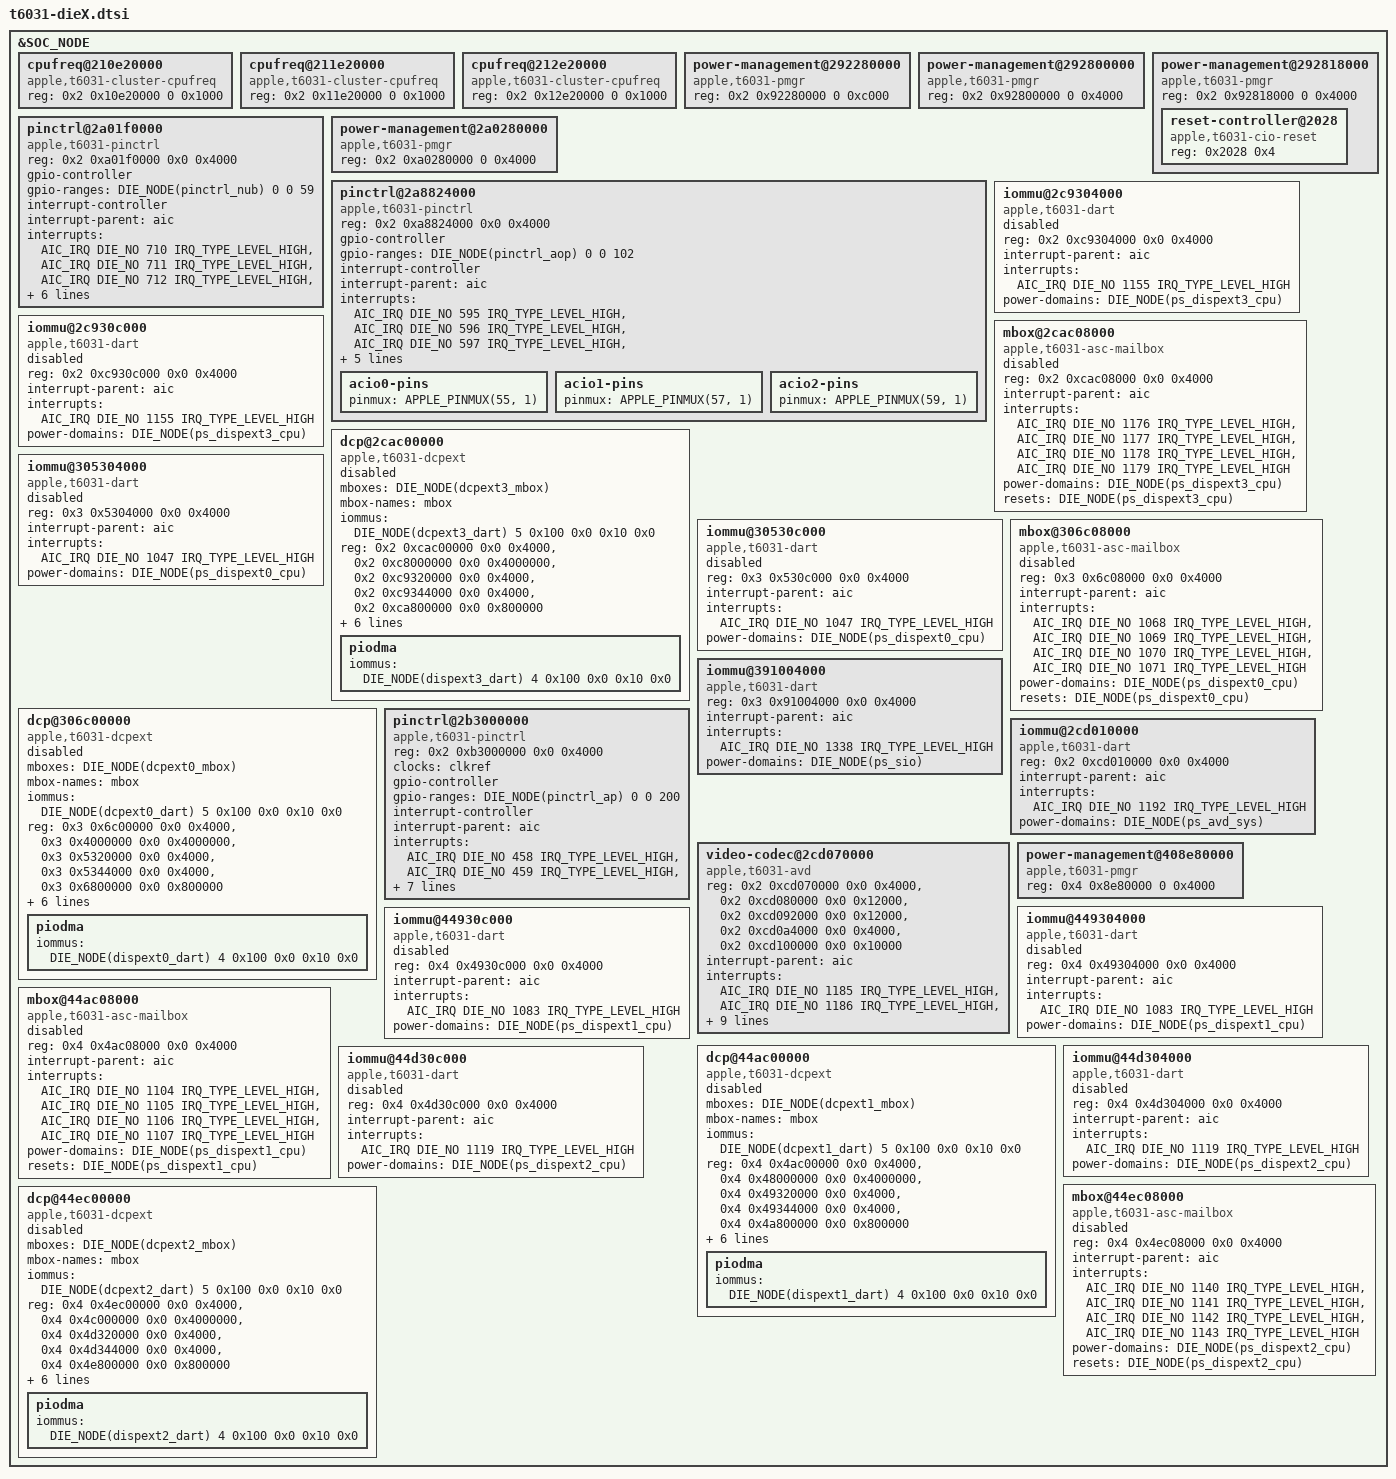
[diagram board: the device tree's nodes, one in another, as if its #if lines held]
// SPDX-License-Identifier: GPL-2.0+ OR MIT
/*
 * Nodes present on both dies of T6032 (M3 Ultra) and present on T6031 / T6034
 * (M3 Max).
 *
 * Copyright The Asahi Linux Contributors
 */

&SOC_NODE {
	DIE_NODE(cpufreq_e): cpufreq@210e20000 {
		compatible = "apple,t6031-cluster-cpufreq", "apple,t8112-cluster-cpufreq";
		reg = <0x2 0x10e20000 0 0x1000>;
		#performance-domain-cells = <0>;
	};

	DIE_NODE(cpufreq_p0): cpufreq@211e20000 {
		compatible = "apple,t6031-cluster-cpufreq", "apple,t8112-cluster-cpufreq";
		reg = <0x2 0x11e20000 0 0x1000>;
		#performance-domain-cells = <0>;
	};

	DIE_NODE(cpufreq_p1): cpufreq@212e20000 {
		compatible = "apple,t6031-cluster-cpufreq", "apple,t8112-cluster-cpufreq";
		reg = <0x2 0x12e20000 0 0x1000>;
		#performance-domain-cells = <0>;
	};

	DIE_NODE(pmgr): power-management@292280000 {
		compatible = "apple,t6031-pmgr", "apple,t8103-pmgr",
			     "syscon", "simple-mfd";
		reg = <0x2 0x92280000 0 0xc000>;
		#address-cells = <1>;
		#size-cells = <1>;
	};

	DIE_NODE(pmgr1): power-management@292800000 {
		compatible = "apple,t6031-pmgr", "apple,t8103-pmgr",
			     "syscon", "simple-mfd";
		reg = <0x2 0x92800000 0 0x4000>;
		#address-cells = <1>;
		#size-cells = <1>;
	};

	DIE_NODE(pmgr_cio): power-management@292818000 {
		compatible = "apple,t6031-pmgr", "apple,t8103-pmgr", "syscon", "simple-mfd";
		#address-cells = <1>;
		#size-cells = <1>;

		reg = <0x2 0x92818000 0 0x4000>;

		DIE_NODE(cio_reset): reset-controller@2028 {
			compatible = "apple,t6031-cio-reset", "apple,t6000-cio-reset";
			reg = <0x2028 0x4>;
			#reset-cells = <1>;
		};
	};

	DIE_NODE(pinctrl_nub): pinctrl@2a01f0000 {
		compatible = "apple,t6031-pinctrl", "apple,t8103-pinctrl";
		reg = <0x2 0xa01f0000 0x0 0x4000>;

		#gpio-cells = <2>;
		gpio-controller;
		gpio-ranges = <&DIE_NODE(pinctrl_nub) 0 0 59>;

		#interrupt-cells = <2>;
		interrupt-controller;
		interrupt-parent = <&aic>;
		interrupts = <AIC_IRQ DIE_NO 710 IRQ_TYPE_LEVEL_HIGH>,
			     <AIC_IRQ DIE_NO 711 IRQ_TYPE_LEVEL_HIGH>,
			     <AIC_IRQ DIE_NO 712 IRQ_TYPE_LEVEL_HIGH>,
			     <AIC_IRQ DIE_NO 713 IRQ_TYPE_LEVEL_HIGH>,
			     <AIC_IRQ DIE_NO 714 IRQ_TYPE_LEVEL_HIGH>,
			     <AIC_IRQ DIE_NO 715 IRQ_TYPE_LEVEL_HIGH>,
			     <AIC_IRQ DIE_NO 716 IRQ_TYPE_LEVEL_HIGH>;

		power-domains = <&DIE_NODE(ps_nub_gpio)>;
		apple,npins = <59>;
	};

	DIE_NODE(pmgr_mini): power-management@2a0280000 {
		compatible = "apple,t6031-pmgr", "apple,t8103-pmgr",
			     "syscon", "simple-mfd";
		reg = <0x2 0xa0280000 0 0x4000>;
		#address-cells = <1>;
		#size-cells = <1>;
	};

	DIE_NODE(pinctrl_aop): pinctrl@2a8824000 {
		compatible = "apple,t6031-pinctrl", "apple,t8103-pinctrl";
		reg = <0x2 0xa8824000 0x0 0x4000>;

		#gpio-cells = <2>;
		gpio-controller;
		gpio-ranges = <&DIE_NODE(pinctrl_aop) 0 0 102>;

		#interrupt-cells = <2>;
		interrupt-controller;
		interrupt-parent = <&aic>;
		interrupts = <AIC_IRQ DIE_NO 595 IRQ_TYPE_LEVEL_HIGH>,
			     <AIC_IRQ DIE_NO 596 IRQ_TYPE_LEVEL_HIGH>,
			     <AIC_IRQ DIE_NO 597 IRQ_TYPE_LEVEL_HIGH>,
			     <AIC_IRQ DIE_NO 598 IRQ_TYPE_LEVEL_HIGH>,
			     <AIC_IRQ DIE_NO 599 IRQ_TYPE_LEVEL_HIGH>,
			     <AIC_IRQ DIE_NO 600 IRQ_TYPE_LEVEL_HIGH>,
			     <AIC_IRQ DIE_NO 601 IRQ_TYPE_LEVEL_HIGH>;

		apple,npins = <102>;

		DIE_NODE(acio0_pins): acio0-pins {
			pinmux = <APPLE_PINMUX(55, 1)>;
		};

		DIE_NODE(acio1_pins): acio1-pins {
			pinmux = <APPLE_PINMUX(57, 1)>;
		};

		DIE_NODE(acio2_pins): acio2-pins {
			pinmux = <APPLE_PINMUX(59, 1)>;
		};
	};

	DIE_NODE(dispext3_dart): iommu@2c9304000 {
		compatible = "apple,t6031-dart", "apple,t8110-dart";
		reg = <0x2 0xc9304000 0x0 0x4000>;
		#iommu-cells = <5>;
		interrupt-parent = <&aic>;
		interrupts = <AIC_IRQ DIE_NO 1155 IRQ_TYPE_LEVEL_HIGH>;
		power-domains = <&DIE_NODE(ps_dispext3_cpu)>;
		status = "disabled";
	};

	DIE_NODE(dcpext3_dart): iommu@2c930c000 {
		compatible = "apple,t6031-dart", "apple,t8110-dart";
		reg = <0x2 0xc930c000 0x0 0x4000>;
		#iommu-cells = <5>;
		interrupt-parent = <&aic>;
		interrupts = <AIC_IRQ DIE_NO 1155 IRQ_TYPE_LEVEL_HIGH>;
		power-domains = <&DIE_NODE(ps_dispext3_cpu)>;
		status = "disabled";
	};

	DIE_NODE(dcpext3_mbox): mbox@2cac08000 {
		compatible = "apple,t6031-asc-mailbox", "apple,asc-mailbox-v4";
		reg = <0x2 0xcac08000 0x0 0x4000>;
		interrupt-parent = <&aic>;
		interrupts = <AIC_IRQ DIE_NO 1176 IRQ_TYPE_LEVEL_HIGH>,
			     <AIC_IRQ DIE_NO 1177 IRQ_TYPE_LEVEL_HIGH>,
			     <AIC_IRQ DIE_NO 1178 IRQ_TYPE_LEVEL_HIGH>,
			     <AIC_IRQ DIE_NO 1179 IRQ_TYPE_LEVEL_HIGH>;
		interrupt-names = "send-empty", "send-not-empty",
				  "recv-empty", "recv-not-empty";
		#mbox-cells = <0>;
		power-domains = <&DIE_NODE(ps_dispext3_cpu)>;
		resets = <&DIE_NODE(ps_dispext3_cpu)>;
		status = "disabled";
	};

	DIE_NODE(dcpext3):  dcp@2cac00000 {
		compatible = "apple,t6031-dcpext", "apple,dcpext";
		mboxes = <&DIE_NODE(dcpext3_mbox)>;
		mbox-names = "mbox";
		iommus = <&DIE_NODE(dcpext3_dart) 5 0x100 0x0 0x10 0x0>;

		reg-names = "coproc", "disp-0", "disp-1", "disp-2", "disp-3";
		reg = <0x2 0xcac00000 0x0 0x4000>,
		      <0x2 0xc8000000 0x0 0x4000000>,
		      <0x2 0xc9320000 0x0 0x4000>,
		      <0x2 0xc9344000 0x0 0x4000>,
		      <0x2 0xca800000 0x0 0x800000>;
		power-domains = <&DIE_NODE(ps_dispext3_cpu)>;
		resets = <&DIE_NODE(ps_dispext3_cpu)>;
		clocks = <&DIE_NODE(clk_dispext3)>;
		phandle = <&DIE_NODE(dcpext3)>;
		// required bus properties for 'piodma' subdevice
		#address-cells = <2>;
		#size-cells = <2>;
		apple,bw-scratch = <&pmgr_dcp 0 4 0x1228>;
		apple,dcp-index = <3>;
		apple,iomfb-surfaces = <1 1 0 1>;
		status = "disabled";

		piodma {
			iommus = <&DIE_NODE(dispext3_dart) 4 0x100 0x0 0x10 0x0>;
		};
	};

	DIE_NODE(dispext0_dart): iommu@305304000 {
		compatible = "apple,t6031-dart", "apple,t8110-dart";
		reg = <0x3 0x5304000 0x0 0x4000>;
		#iommu-cells = <5>;
		interrupt-parent = <&aic>;
		interrupts = <AIC_IRQ DIE_NO 1047 IRQ_TYPE_LEVEL_HIGH>;
		power-domains = <&DIE_NODE(ps_dispext0_cpu)>;
		status = "disabled";
	};

	DIE_NODE(dcpext0_dart): iommu@30530c000 {
		compatible = "apple,t6031-dart", "apple,t8110-dart";
		reg = <0x3 0x530c000 0x0 0x4000>;
		#iommu-cells = <5>;
		interrupt-parent = <&aic>;
		interrupts = <AIC_IRQ DIE_NO 1047 IRQ_TYPE_LEVEL_HIGH>;
		power-domains = <&DIE_NODE(ps_dispext0_cpu)>;
		status = "disabled";
	};

	DIE_NODE(dcpext0_mbox): mbox@306c08000 {
		compatible = "apple,t6031-asc-mailbox", "apple,asc-mailbox-v4";
		reg = <0x3 0x6c08000 0x0 0x4000>;
		interrupt-parent = <&aic>;
		interrupts = <AIC_IRQ DIE_NO 1068 IRQ_TYPE_LEVEL_HIGH>,
			     <AIC_IRQ DIE_NO 1069 IRQ_TYPE_LEVEL_HIGH>,
			     <AIC_IRQ DIE_NO 1070 IRQ_TYPE_LEVEL_HIGH>,
			     <AIC_IRQ DIE_NO 1071 IRQ_TYPE_LEVEL_HIGH>;
		interrupt-names = "send-empty", "send-not-empty",
				  "recv-empty", "recv-not-empty";
		#mbox-cells = <0>;
		power-domains = <&DIE_NODE(ps_dispext0_cpu)>;
		resets = <&DIE_NODE(ps_dispext0_cpu)>;
		status = "disabled";
	};

	DIE_NODE(dcpext0):  dcp@306c00000 {
		compatible = "apple,t6031-dcpext", "apple,dcpext";
		mboxes = <&DIE_NODE(dcpext0_mbox)>;
		mbox-names = "mbox";
		iommus = <&DIE_NODE(dcpext0_dart) 5 0x100 0x0 0x10 0x0>;

		reg-names = "coproc", "disp-0", "disp-1", "disp-2", "disp-3";
		reg = <0x3 0x6c00000 0x0 0x4000>,
		      <0x3 0x4000000 0x0 0x4000000>,
		      <0x3 0x5320000 0x0 0x4000>,
		      <0x3 0x5344000 0x0 0x4000>,
		      <0x3 0x6800000 0x0 0x800000>;
		power-domains = <&DIE_NODE(ps_dispext0_cpu)>;
		resets = <&DIE_NODE(ps_dispext0_cpu)>;
		clocks = <&DIE_NODE(clk_dispext0)>;
		phandle = <&DIE_NODE(dcpext0)>;
		// required bus properties for 'piodma' subdevice
		#address-cells = <2>;
		#size-cells = <2>;
		apple,bw-scratch = <&pmgr_dcp 0 4 0x1210>;
		apple,dcp-index = <0>;
		apple,iomfb-surfaces = <1 1 0 1>;
		status = "disabled";

		piodma {
			iommus = <&DIE_NODE(dispext0_dart) 4 0x100 0x0 0x10 0x0>;
		};
	};

	DIE_NODE(sio_dart): iommu@391004000 {
		compatible = "apple,t6031-dart", "apple,t8110-dart";
		reg = <0x3 0x91004000 0x0 0x4000>;
		interrupt-parent = <&aic>;
		interrupts = <AIC_IRQ DIE_NO 1338 IRQ_TYPE_LEVEL_HIGH>;
		#iommu-cells = <1>;
		power-domains = <&DIE_NODE(ps_sio)>;
	};

	DIE_NODE(pinctrl_ap): pinctrl@2b3000000 {
		compatible = "apple,t6031-pinctrl", "apple,t8103-pinctrl";
		reg = <0x2 0xb3000000 0x0 0x4000>;

		clocks = <&clkref>;

		#gpio-cells = <2>;
		gpio-controller;
		gpio-ranges = <&DIE_NODE(pinctrl_ap) 0 0 200>;

		#interrupt-cells = <2>;
		interrupt-controller;
		interrupt-parent = <&aic>;
		interrupts = <AIC_IRQ DIE_NO 458 IRQ_TYPE_LEVEL_HIGH>,
			     <AIC_IRQ DIE_NO 459 IRQ_TYPE_LEVEL_HIGH>,
			     <AIC_IRQ DIE_NO 460 IRQ_TYPE_LEVEL_HIGH>,
			     <AIC_IRQ DIE_NO 461 IRQ_TYPE_LEVEL_HIGH>,
			     <AIC_IRQ DIE_NO 462 IRQ_TYPE_LEVEL_HIGH>,
			     <AIC_IRQ DIE_NO 463 IRQ_TYPE_LEVEL_HIGH>,
			     <AIC_IRQ DIE_NO 464 IRQ_TYPE_LEVEL_HIGH>;

		power-domains = <&DIE_NODE(ps_gpio)>;
		apple,npins = <200>;
	};

	DIE_NODE(avd_dart): iommu@2cd010000 {
		compatible = "apple,t6031-dart", "apple,t8110-dart";
		reg = <0x2 0xcd010000 0x0 0x4000>;
		interrupt-parent = <&aic>;
		interrupts = <AIC_IRQ DIE_NO 1192 IRQ_TYPE_LEVEL_HIGH>;
		#iommu-cells = <1>;
		power-domains = <&DIE_NODE(ps_avd_sys)>;
	};

	video-codec@2cd070000 {
		compatible = "apple,t6031-avd", "apple,t8122-avd";
		reg = <0x2 0xcd070000 0x0 0x4000>,
		      <0x2 0xcd080000 0x0 0x12000>,
		      <0x2 0xcd092000 0x0 0x12000>,
		      <0x2 0xcd0a4000 0x0 0x4000>,
		      <0x2 0xcd100000 0x0 0x10000>;
		reg-names = "piodma", "code", "sram", "mbox", "ctrl";
		interrupt-parent = <&aic>;
		interrupts = <AIC_IRQ DIE_NO 1185 IRQ_TYPE_LEVEL_HIGH>,
			     <AIC_IRQ DIE_NO 1186 IRQ_TYPE_LEVEL_HIGH>,
			     <AIC_IRQ DIE_NO 1187 IRQ_TYPE_LEVEL_HIGH>,
			     <AIC_IRQ DIE_NO 1188 IRQ_TYPE_LEVEL_HIGH>,
			     <AIC_IRQ DIE_NO 1189 IRQ_TYPE_LEVEL_HIGH>,
			     <AIC_IRQ DIE_NO 1190 IRQ_TYPE_LEVEL_HIGH>,
			     <AIC_IRQ DIE_NO 1191 IRQ_TYPE_LEVEL_HIGH>;
		interrupt-names = "mbox0", "mbox1", "mbox2", "mbox3",
				  "flag0", "flag1", "piodma";
		iommus = <&DIE_NODE(avd_dart) 0>, <&DIE_NODE(avd_dart) 1>;
		#if defined(APPLE_USE_PMP)
		power-domains = <&DIE_NODE(pmp_report_avd_sys)>;
		#else
		power-domains = <&DIE_NODE(ps_avd_sys)>;
		#endif
		resets = <&DIE_NODE(ps_avd_sys)>;
	};

	DIE_NODE(pmgr_gfx): power-management@408e80000 {
		compatible = "apple,t6031-pmgr", "apple,t8103-pmgr",
			     "syscon", "simple-mfd";
		reg = <0x4 0x8e80000 0 0x4000>;
		#address-cells = <1>;
		#size-cells = <1>;
	};

	DIE_NODE(dispext1_dart): iommu@449304000 {
		compatible = "apple,t6031-dart", "apple,t8110-dart";
		reg = <0x4 0x49304000 0x0 0x4000>;
		#iommu-cells = <5>;
		interrupt-parent = <&aic>;
		interrupts = <AIC_IRQ DIE_NO 1083 IRQ_TYPE_LEVEL_HIGH>;
		power-domains = <&DIE_NODE(ps_dispext1_cpu)>;
		status = "disabled";
	};

	DIE_NODE(dcpext1_dart): iommu@44930c000 {
		compatible = "apple,t6031-dart", "apple,t8110-dart";
		reg = <0x4 0x4930c000 0x0 0x4000>;
		#iommu-cells = <5>;
		interrupt-parent = <&aic>;
		interrupts = <AIC_IRQ DIE_NO 1083 IRQ_TYPE_LEVEL_HIGH>;
		power-domains = <&DIE_NODE(ps_dispext1_cpu)>;
		status = "disabled";
	};

	DIE_NODE(dcpext1_mbox): mbox@44ac08000 {
		compatible = "apple,t6031-asc-mailbox", "apple,asc-mailbox-v4";
		reg = <0x4 0x4ac08000 0x0 0x4000>;
		interrupt-parent = <&aic>;
		interrupts = <AIC_IRQ DIE_NO 1104 IRQ_TYPE_LEVEL_HIGH>,
			     <AIC_IRQ DIE_NO 1105 IRQ_TYPE_LEVEL_HIGH>,
			     <AIC_IRQ DIE_NO 1106 IRQ_TYPE_LEVEL_HIGH>,
			     <AIC_IRQ DIE_NO 1107 IRQ_TYPE_LEVEL_HIGH>;
		interrupt-names = "send-empty", "send-not-empty",
				  "recv-empty", "recv-not-empty";
		#mbox-cells = <0>;
		power-domains = <&DIE_NODE(ps_dispext1_cpu)>;
		resets = <&DIE_NODE(ps_dispext1_cpu)>;
		status = "disabled";
	};

	DIE_NODE(dcpext1):  dcp@44ac00000 {
		compatible = "apple,t6031-dcpext", "apple,dcpext";
		mboxes = <&DIE_NODE(dcpext1_mbox)>;
		mbox-names = "mbox";
		iommus = <&DIE_NODE(dcpext1_dart) 5 0x100 0x0 0x10 0x0>;

		reg-names = "coproc", "disp-0", "disp-1", "disp-2", "disp-3";
		reg = <0x4 0x4ac00000 0x0 0x4000>,
		      <0x4 0x48000000 0x0 0x4000000>,
		      <0x4 0x49320000 0x0 0x4000>,
		      <0x4 0x49344000 0x0 0x4000>,
		      <0x4 0x4a800000 0x0 0x800000>;
		power-domains = <&DIE_NODE(ps_dispext1_cpu)>;
		resets = <&DIE_NODE(ps_dispext1_cpu)>;
		clocks = <&DIE_NODE(clk_dispext1)>;
		phandle = <&DIE_NODE(dcpext1)>;
		// required bus properties for 'piodma' subdevice
		#address-cells = <2>;
		#size-cells = <2>;
		apple,bw-scratch = <&pmgr_dcp 0 4 0x1218>;
		apple,dcp-index = <1>;
		apple,iomfb-surfaces = <1 1 0 1>;
		status = "disabled";

		piodma {
			iommus = <&DIE_NODE(dispext1_dart) 4 0x100 0x0 0x10 0x0>;
		};
	};

	DIE_NODE(dispext2_dart): iommu@44d304000 {
		compatible = "apple,t6031-dart", "apple,t8110-dart";
		reg = <0x4 0x4d304000 0x0 0x4000>;
		#iommu-cells = <5>;
		interrupt-parent = <&aic>;
		interrupts = <AIC_IRQ DIE_NO 1119 IRQ_TYPE_LEVEL_HIGH>;
		power-domains = <&DIE_NODE(ps_dispext2_cpu)>;
		status = "disabled";
	};

	DIE_NODE(dcpext2_dart): iommu@44d30c000 {
		compatible = "apple,t6031-dart", "apple,t8110-dart";
		reg = <0x4 0x4d30c000 0x0 0x4000>;
		#iommu-cells = <5>;
		interrupt-parent = <&aic>;
		interrupts = <AIC_IRQ DIE_NO 1119 IRQ_TYPE_LEVEL_HIGH>;
		power-domains = <&DIE_NODE(ps_dispext2_cpu)>;
		status = "disabled";
	};

	DIE_NODE(dcpext2_mbox): mbox@44ec08000 {
		compatible = "apple,t6031-asc-mailbox", "apple,asc-mailbox-v4";
		reg = <0x4 0x4ec08000 0x0 0x4000>;
		interrupt-parent = <&aic>;
		interrupts = <AIC_IRQ DIE_NO 1140 IRQ_TYPE_LEVEL_HIGH>,
			     <AIC_IRQ DIE_NO 1141 IRQ_TYPE_LEVEL_HIGH>,
			     <AIC_IRQ DIE_NO 1142 IRQ_TYPE_LEVEL_HIGH>,
			     <AIC_IRQ DIE_NO 1143 IRQ_TYPE_LEVEL_HIGH>;
		interrupt-names = "send-empty", "send-not-empty",
				  "recv-empty", "recv-not-empty";
		#mbox-cells = <0>;
		power-domains = <&DIE_NODE(ps_dispext2_cpu)>;
		resets = <&DIE_NODE(ps_dispext2_cpu)>;
		status = "disabled";
	};

	DIE_NODE(dcpext2):  dcp@44ec00000 {
		compatible = "apple,t6031-dcpext", "apple,dcpext";
		mboxes = <&DIE_NODE(dcpext2_mbox)>;
		mbox-names = "mbox";
		iommus = <&DIE_NODE(dcpext2_dart) 5 0x100 0x0 0x10 0x0>;

		reg-names = "coproc", "disp-0", "disp-1", "disp-2", "disp-3";
		reg = <0x4 0x4ec00000 0x0 0x4000>,
		      <0x4 0x4c000000 0x0 0x4000000>,
		      <0x4 0x4d320000 0x0 0x4000>,
		      <0x4 0x4d344000 0x0 0x4000>,
		      <0x4 0x4e800000 0x0 0x800000>;
		power-domains = <&DIE_NODE(ps_dispext2_cpu)>;
		resets = <&DIE_NODE(ps_dispext2_cpu)>;
		clocks = <&DIE_NODE(clk_dispext2)>;
		phandle = <&DIE_NODE(dcpext2)>;
		// required bus properties for 'piodma' subdevice
		#address-cells = <2>;
		#size-cells = <2>;
		apple,bw-scratch = <&pmgr_dcp 0 4 0x1220>;
		apple,dcp-index = <2>;
		apple,iomfb-surfaces = <1 1 0 1>;
		status = "disabled";

		piodma {
			iommus = <&DIE_NODE(dispext2_dart) 4 0x100 0x0 0x10 0x0>;
		};
	};
};
